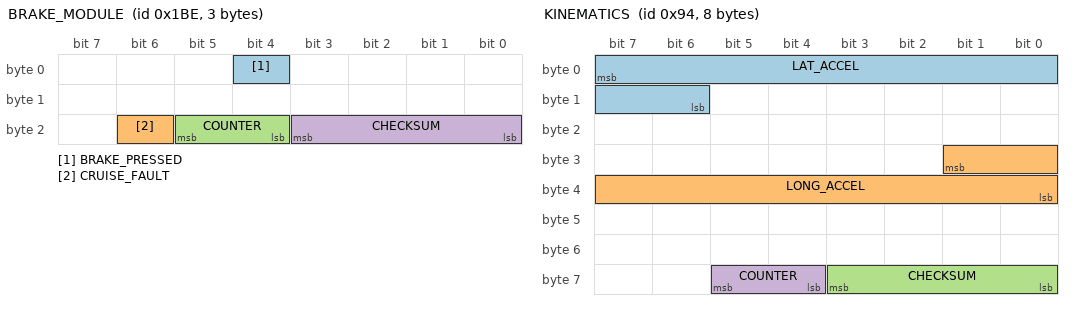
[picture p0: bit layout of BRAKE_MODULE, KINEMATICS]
BO_ 446 BRAKE_MODULE: 3 VSA
 SG_ BRAKE_PRESSED : 4|1@0+ (1,0) [0|1] "" XXX
 SG_ CRUISE_FAULT : 22|1@0+ (1,0) [0|1] "" XXX
 SG_ COUNTER : 21|2@0+ (1,0) [0|3] "" XXX
 SG_ CHECKSUM : 19|4@0+ (1,0) [0|15] "" XXX

BO_ 148 KINEMATICS: 8 XXX
 SG_ LAT_ACCEL : 7|10@0+ (-0.035,17.92) [-20|20] "m/s2" EON
 SG_ LONG_ACCEL : 25|10@0+ (-0.035,17.92) [-20|20] "m/s2" EON
 SG_ CHECKSUM : 59|4@0+ (1,0) [0|3] "" EON
 SG_ COUNTER : 61|2@0+ (1,0) [0|3] "" EON

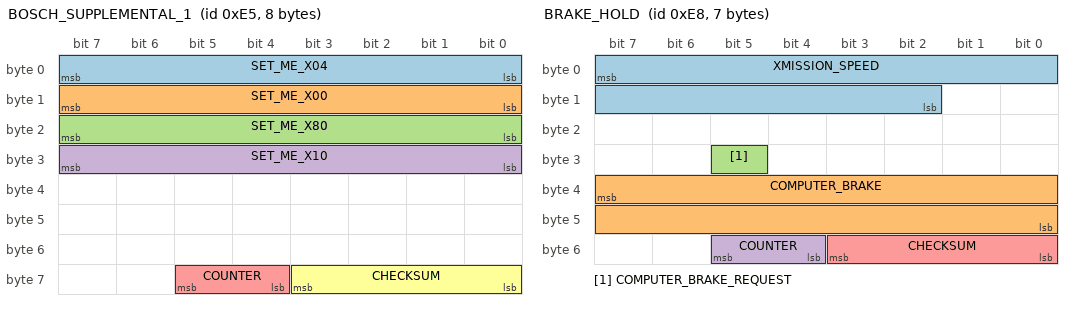
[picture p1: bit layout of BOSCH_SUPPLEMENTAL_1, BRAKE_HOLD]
BO_ 229 BOSCH_SUPPLEMENTAL_1: 8 XXX
 SG_ SET_ME_X04 : 0|8@1+ (1,0) [0|255] "" XXX
 SG_ SET_ME_X00 : 8|8@1+ (1,0) [0|255] "" XXX
 SG_ SET_ME_X80 : 16|8@1+ (1,0) [0|255] "" XXX
 SG_ SET_ME_X10 : 24|8@1+ (1,0) [0|255] "" XXX
 SG_ COUNTER : 61|2@0+ (1,0) [0|3] "" XXX
 SG_ CHECKSUM : 59|4@0+ (1,0) [0|15] "" XXX

BO_ 232 BRAKE_HOLD: 7 XXX
 SG_ XMISSION_SPEED : 7|14@0- (1,0) [1|0] "" XXX
 SG_ COMPUTER_BRAKE : 39|16@0+ (1,0) [0|0] "" XXX
 SG_ COMPUTER_BRAKE_REQUEST : 29|1@0+ (1,0) [0|0] "" XXX
 SG_ COUNTER : 53|2@0+ (1,0) [0|3] "" XXX
 SG_ CHECKSUM : 51|4@0+ (1,0) [0|15] "" XXX

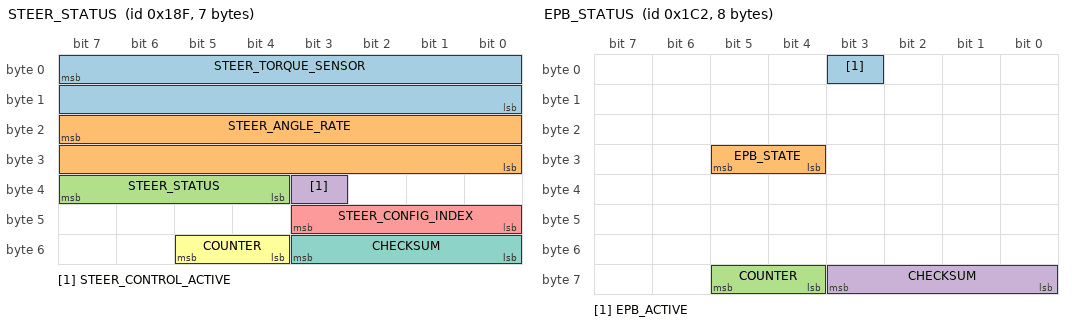
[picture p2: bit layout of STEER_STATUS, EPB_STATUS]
BO_ 399 STEER_STATUS: 7 EPS
 SG_ STEER_TORQUE_SENSOR : 7|16@0- (-1,0) [-31000|31000] "tbd" EON
 SG_ STEER_ANGLE_RATE : 23|16@0- (-0.1,0) [-31000|31000] "deg/s" EON
 SG_ STEER_STATUS : 39|4@0+ (1,0) [0|15] "" EON
 SG_ STEER_CONTROL_ACTIVE : 35|1@0+ (1,0) [0|1] "" EON
 SG_ STEER_CONFIG_INDEX : 43|4@0+ (1,0) [0|15] "" EON
 SG_ COUNTER : 53|2@0+ (1,0) [0|3] "" EON
 SG_ CHECKSUM : 51|4@0+ (1,0) [0|15] "" EON

BO_ 450 EPB_STATUS: 8 EPB
 SG_ EPB_ACTIVE : 3|1@0+ (1,0) [0|1] "" EON
 SG_ EPB_STATE : 29|2@0+ (1,0) [0|3] "" EON
 SG_ COUNTER : 61|2@0+ (1,0) [0|3] "" XXX
 SG_ CHECKSUM : 59|4@0+ (1,0) [0|15] "" XXX

CM_ SG_ 450 EPB_STATE "3: On, 2: Disengaging, 1: Engaging, 0: Off";

VAL_ 399 STEER_STATUS 6 "tmp_fault" 5 "fault_1" 4 "no_torque_alert_2" 3 "low_speed_lockout" 2 "no_torque_alert_1" 0 "normal";
